# LPC8N04 register map
File version: 0.1
CPU: CM0PLUS r0p0, little endian, no MPU, no FPU, 2 interrupt priority bits
Registers are 32-bit, read-write, no defined reset value unless marked. A register's access mark holds for its fields unless they carry their own. Offsets are from the block's base; [hi:lo] are bit positions; 'fields as' and 'values as' point back to an identical list.

## SYSCON — System Configuration
Base 0x40048000
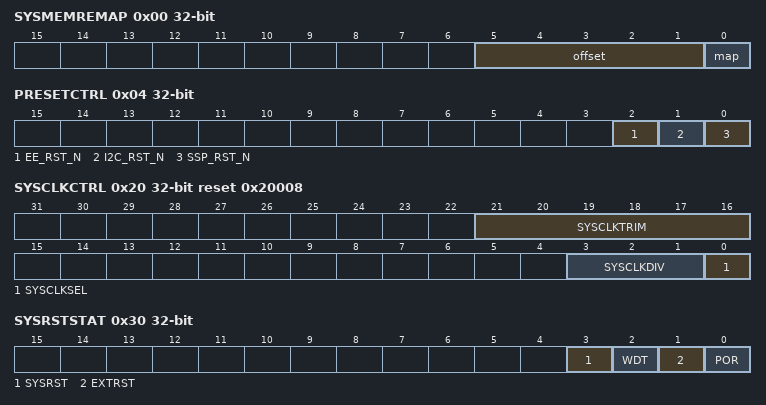
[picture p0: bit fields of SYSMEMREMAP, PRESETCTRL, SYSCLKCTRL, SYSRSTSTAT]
0x00 SYSMEMREMAP — System memory remap
  [5:1] offset — System memory remap offset
    0=NA0 (Interrupt vectors in flash or remapped to SRAM but not offset); 1=NA1 (Interrupt vectors offset in flash or SRAM to 1K word segment); 8=NA2 (Interrupt vectors offset in flash to 1K word segment 8 to 31)
  [0] map — Interrupt vector remap
    0=FLASH (Interrupt vectors reside in Flash); 1=SRAM (Interrupt vectors reside in SRAM)
0x04 PRESETCTRL — Peripheral reset control
  [2] EE_RST_N — EEPROM nvmc reset control
    0=ASSERTED (Resets the EEPROM controller); 1=DEASSERTED (Reset de-asserted)
  [1] I2C_RST_N — I2C reset control
    0=ASSERTED (Resets the I2C peripheral); 1=DEASSERTED (I2C reset de-asserted)
  [0] SSP_RST_N — SPI/SSP reset control
    0=ASSERTED (Resets the SPI peripheral); 1=DEASSERTED (SPI reset deasserted)
0x20 SYSCLKCTRL reset 0x20008 (reset mask 0x0) — System clock control register
  [21:16] SYSCLKTRIM — System FRO trim value (6-bit)
  [3:1] SYSCLKDIV — System clock divider
    0=NO_DIV (no division (output 8 MHz from SFRO)); 1=DIV_2 (divide-by-2 (output 4 MHz from SFRO)); 2=DIV_4 (divide-by-4 (output 2 MHz from SFRO)); 3=DIV_8 (divide-by-8 (output 1 MHz from SFRO)); 4=DIV_16 (divide-by-16 (output 500 kHz from SFRO)); 5=DIV_32 (divide-by-32 (output 250 kHz from SFRO)); 6=DIV_64 (divide-by-64 (output 125 kHz from SFRO)); 7=DIV_128 (divide-by-128 (output 62.5 kHz from SFRO))
  [0] SYSCLKSEL — System clock selection
    0=NA0 (Internal 8 MHz FRO); 1=NA1 (External clock input)
0x24 SYSCLKUEN — System clock update enable
  [0] ENA — Enable system clock source update
    0=NA0 (no update); 1=NA1 (update clock source)
0x30 SYSRSTSTAT — System reset status register
  [3] SYSRST — Status of software system reset (ARM AIRCR register SYSRESETREQ bit was set)
    0=NOT_DETECTED (No software reset detected); 1=DETECTED (Software reset detected)
  [2] WDT — Status of the Watchdog reset
    0=NOT_DETECTED (no WDT reset detected); 1=DETECTED (WDT reset detected)
  [1] EXTRST — Status of external RESETN pin
    0=NOT_DETECTED (No RESETN event detected); 1=DETECTED (External reset detected)
  [0] POR — POR reset status
    0=NOT_DETECTED (no POR detected); 1=DETECTED (POR detected)
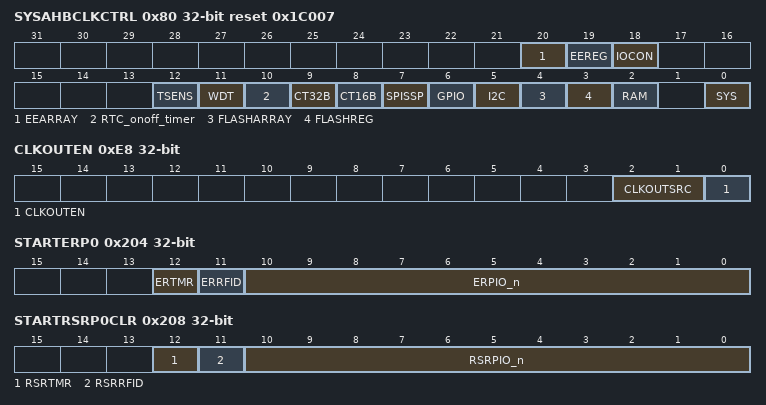
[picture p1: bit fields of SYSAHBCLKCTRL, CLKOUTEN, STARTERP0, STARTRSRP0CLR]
0x80 SYSAHBCLKCTRL reset 0x1C007 (reset mask 0x0) — AHB clock control
  [20] EEARRAY — Enable clock for EEPROM array access
    0=DISABLED; 1=ENABLED
  [19] EEREG — Enable clock for EEPROM register interface
    0=DISABLED; 1=ENABLED
  [18] IOCON — Enable clock for I/O configuration block
    0=DISABLED; 1=ENABLED
  [12] TSENS — Enable clock for temperature sensor
    0=DISABLED; 1=ENABLED
  [11] WDT — Enable clock for watchdog timer
    0=DISABLED; 1=ENABLED
  [10] RTC_onoff_timer — Enable clock for RTC on/off timer (APB side only, timer unit is clocked by TFRO directly as set by TMRCLKCTRL register)
    0=DISABLED; 1=ENABLED
  [9] CT32B — Enable clock for 32-bit counter/timer
    0=DISABLED; 1=ENABLED
  [8] CT16B — Enable clock for 16-bit counter/timer
    0=DISABLED; 1=ENABLED
  [7] SPISSP — Enable clock for SPI/SSP
    0=DISABLED; 1=ENABLED
  [6] GPIO — Enable clock for GPIO
    0=DISABLED; 1=ENABLED
  [5] I2C — Enable clock for I2C
    0=DISABLED; 1=ENABLED
  [4] FLASHARRAY — Enable clock for Flash array access
    0=DISABLED; 1=ENABLED
  [3] FLASHREG — Enable clock for Flash register interface
    0=DISABLED; 1=ENABLED
  [2] RAM — Enable clock for RAM
    0=DISABLED; 1=ENABLED
  [0] SYS ro — Enable clock for AHB to APB bridge, to the AHB matrix, to the Cortex M0+ FCLK and HCLK, to the SysCon, and to the PMU. This bit is read only.
    1=NA0 (Enable)
0x94 SSPCLKDIV — SPI/SSP clock divider
  [7:0] DIV — SPI_CLK clock divider values: (0) disable. (1-255) divide-by-DIV
0xD0 WDTCLKSEL — Watchdog timer clock selector
  [1:0] SEL — WDT clock source
    0=SFRO (System FRO); 1=NA1 (External clock pin); 2=VSS (VSS (no clock))
0xD4 WDTCLKUEN — Watchdog timer clock update enable
  [0] ENA — Enable WDT clock source update
    0=NA0 (no update); 1=NA1 (update clock source)
0xD8 WDTCLKDIV — Watchdog timer clock divider
  [7:0] DIV — WDT clock divider values: 0: disable WDT_PCLK, 1-255: divide by 1-255
0xE8 CLKOUTEN — CLKOUT enable
  [2:1] CLKOUTSRC — output SFRO
    0=SFRO (8MHz); 1=SYSTEM_CLK (output system clock (62.5 kHz - 8 MHz)); 2=TFRO (output TFRO (32 kHz)); 3=NFC_CLK (output NFC clock (1.695 MHz))
  [0] CLKOUTEN — disable output
    0=DISABLED (disable output); 1=ENABLED (enable output)
0x154 SYSTCKCAL reset 0x4 (reset mask 0x0) — System tick counter calibration
  [25:0] CAL — System tick timer calibration value
0x200 STARTAPRP0 — Start logic edge control register 0
  [10:0] APRPIO_n — Edge select for start logic input PIO_n (PIO_10 to PIO_0)
0x204 STARTERP0 — Start logic signal enable register 0
  [12] ERTMR — Enable start signal for start logic input RTC timer
    0=DISABLED; 1=ENABLED
  [11] ERRFID — Enable start signal for start logic input RFID
    0=DISABLED; 1=ENABLED
  [10:0] ERPIO_n — Enable start signal for start logic input PIO_n
0x208 STARTRSRP0CLR wo — Start logic reset register 0
  [12] RSRTMR — Start signal reset for start logic input wakeup timer
    0=DO_NOTHING; 1=RESET (Writing 1 resets the start signal)
  [11] RSRRFID — Start signal reset for start logic input RFID
    0=DO_NOTHING; 1=RESET (Writing 1 resets the start signal)
  [10:0] RSRPIO_n — Start signal reset for start logic input PIO_n
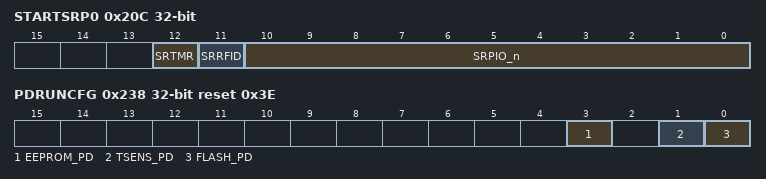
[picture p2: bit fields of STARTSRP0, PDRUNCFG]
0x20C STARTSRP0 ro — Start logic status register 0
  [12] SRTMR — Start signal status for start logic input wakeup timer
    0=CLEARED (no start signal received); 1=SET (start signal received)
  [11] SRRFID — Start signal status for start logic input RFID
    values as SRTMR
  [10:0] SRPIO_n — Start signal status for start logic input PIO
0x234 PDAWAKECFG reset 0x1 (reset mask 0x0) — Power-down states after wake-up from deep-sleep mode
  [0] FLASH_PD — Flash wake-up configuration
    0=POWERED; 1=POWERED_DOWN
0x238 PDRUNCFG reset 0x3E (reset mask 0x0) — power-down configuration register
  [all] fields
    0=POWERED; 1=POWERED_DOWN
  [3] EEPROM_PD — EEPROM power down
  [1] TSENS_PD — Temperature sensor
  [0] FLASH_PD — Flash power down
0x3F4 DEVICE_ID ro
  [31:0] DEVICEID — Part ID number for LPC8N04 derivative
